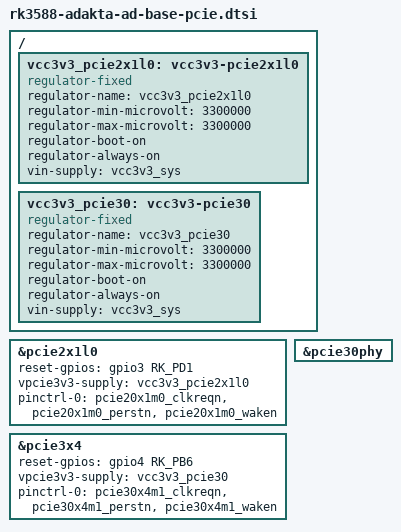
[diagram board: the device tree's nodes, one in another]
// SPDX-License-Identifier: (GPL-2.0+ OR MIT)
/*
 * Copyright (c) 2024 Adakta, Ltd.
 *
 */

/ {
	vcc3v3_pcie2x1l0: vcc3v3-pcie2x1l0 {
		compatible = "regulator-fixed";
		regulator-name = "vcc3v3_pcie2x1l0";
		regulator-min-microvolt = <3300000>;
		regulator-max-microvolt = <3300000>;
		regulator-boot-on;
		regulator-always-on;
		vin-supply = <&vcc3v3_sys>;
	};

	vcc3v3_pcie30: vcc3v3-pcie30 {
		compatible = "regulator-fixed";
		regulator-name = "vcc3v3_pcie30";
		regulator-min-microvolt = <3300000>;
		regulator-max-microvolt = <3300000>;
		regulator-boot-on;
		regulator-always-on;
		vin-supply = <&vcc3v3_sys>;
	};
};

&pcie2x1l0 {
	reset-gpios = <&gpio3 RK_PD1 GPIO_ACTIVE_HIGH>;
	vpcie3v3-supply = <&vcc3v3_pcie2x1l0>;
	pinctrl-names = "default";
	pinctrl-0 = <&pcie20x1m0_clkreqn &pcie20x1m0_perstn &pcie20x1m0_waken>;
	status = "okay";
};

&pcie30phy {
	status = "okay";
};

&pcie3x4 {
	reset-gpios = <&gpio4 RK_PB6 GPIO_ACTIVE_HIGH>;
	vpcie3v3-supply = <&vcc3v3_pcie30>;
	pinctrl-names = "default";
	pinctrl-0 = <&pcie30x4m1_clkreqn &pcie30x4m1_perstn &pcie30x4m1_waken>;
	status = "okay";
};
